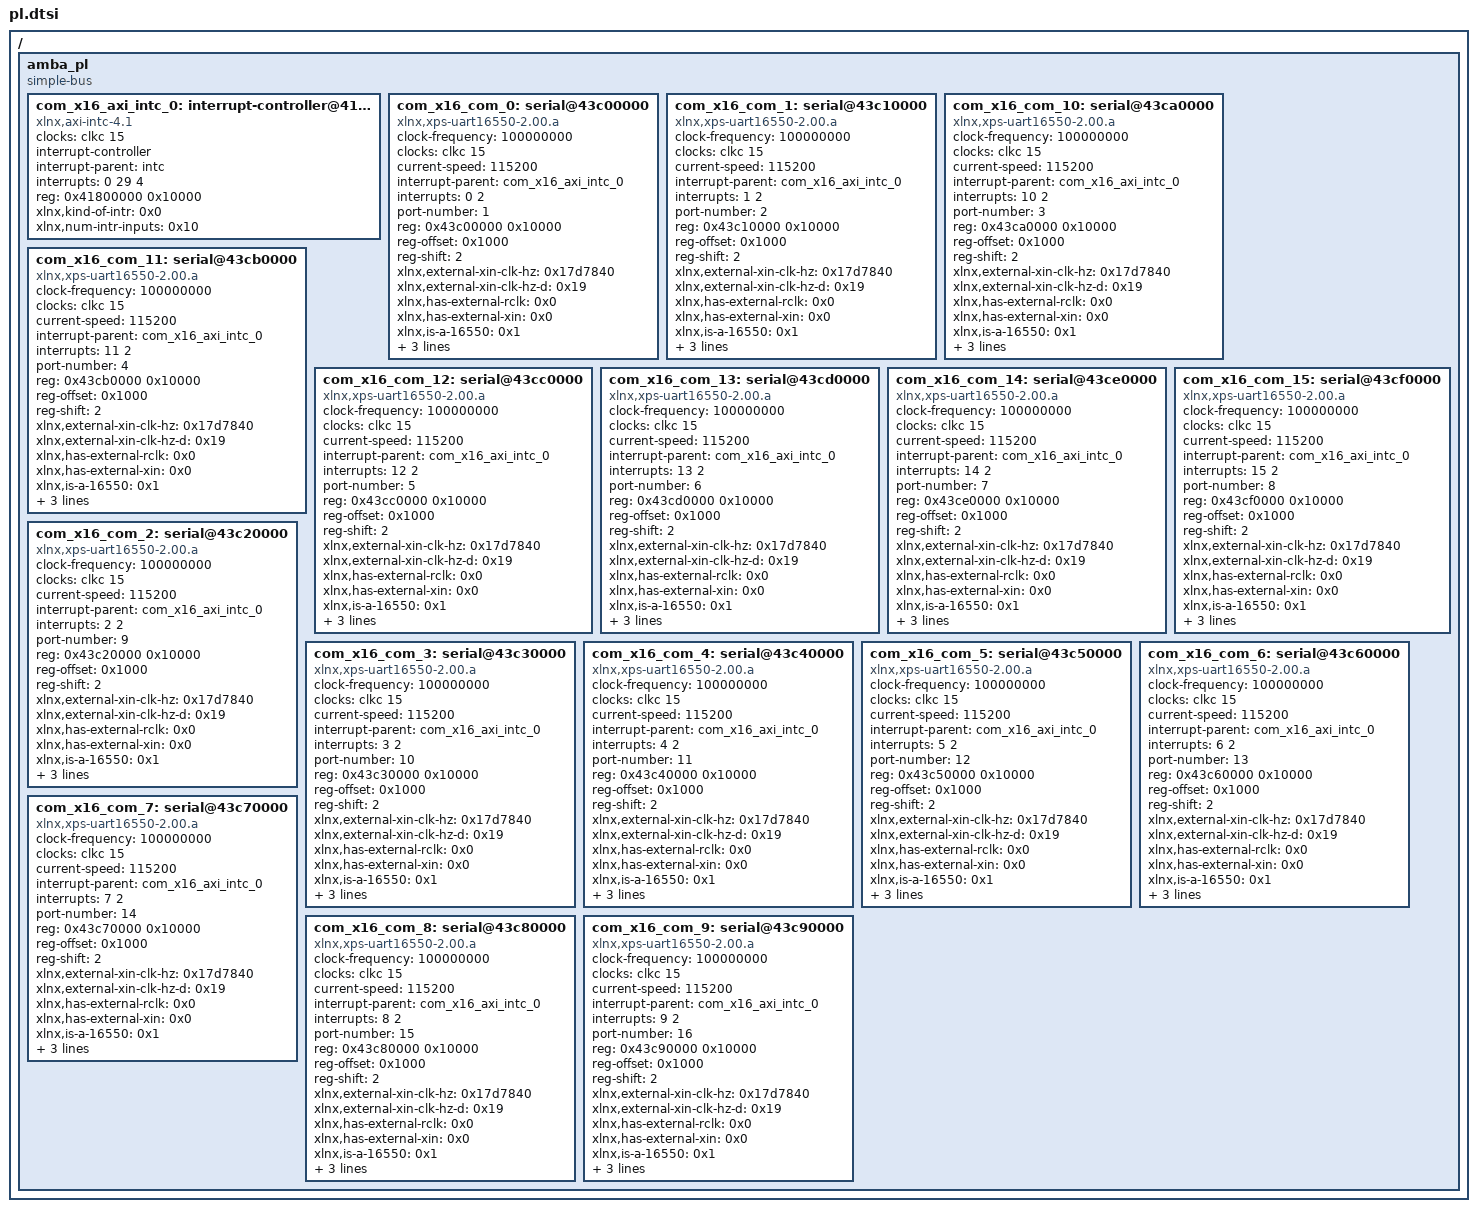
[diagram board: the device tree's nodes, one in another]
/*
 * CAUTION: This file is automatically generated by Xilinx.
 * Version: XSCT 2018.3.1
 * Today is: Tue Mar 17 23:05:40 2020
 */


/ {
	amba_pl: amba_pl {
		#address-cells = <1>;
		#size-cells = <1>;
		compatible = "simple-bus";
		ranges ;
		com_x16_axi_intc_0: interrupt-controller@41800000 {
			#interrupt-cells = <2>;
			clock-names = "s_axi_aclk";
			clocks = <&clkc 15>;
			compatible = "xlnx,axi-intc-4.1", "xlnx,xps-intc-1.00.a";
			interrupt-controller ;
			interrupt-names = "irq";
			interrupt-parent = <&intc>;
			interrupts = <0 29 4>;
			reg = <0x41800000 0x10000>;
			xlnx,kind-of-intr = <0x0>;
			xlnx,num-intr-inputs = <0x10>;
		};
		com_x16_com_0: serial@43c00000 {
			clock-frequency = <100000000>;
			clock-names = "s_axi_aclk";
			clocks = <&clkc 15>;
			compatible = "xlnx,xps-uart16550-2.00.a", "ns16550a";
			current-speed = <115200>;
			device_type = "serial";
			interrupt-names = "ip2intc_irpt";
			interrupt-parent = <&com_x16_axi_intc_0>;
			interrupts = <0 2>;
			port-number = <1>;
			reg = <0x43c00000 0x10000>;
			reg-offset = <0x1000>;
			reg-shift = <2>;
			xlnx,external-xin-clk-hz = <0x17d7840>;
			xlnx,external-xin-clk-hz-d = <0x19>;
			xlnx,has-external-rclk = <0x0>;
			xlnx,has-external-xin = <0x0>;
			xlnx,is-a-16550 = <0x1>;
			xlnx,s-axi-aclk-freq-hz-d = "100.0";
			xlnx,use-modem-ports = <0x1>;
			xlnx,use-user-ports = <0x1>;
		};
		com_x16_com_1: serial@43c10000 {
			clock-frequency = <100000000>;
			clock-names = "s_axi_aclk";
			clocks = <&clkc 15>;
			compatible = "xlnx,xps-uart16550-2.00.a", "ns16550a";
			current-speed = <115200>;
			device_type = "serial";
			interrupt-names = "ip2intc_irpt";
			interrupt-parent = <&com_x16_axi_intc_0>;
			interrupts = <1 2>;
			port-number = <2>;
			reg = <0x43c10000 0x10000>;
			reg-offset = <0x1000>;
			reg-shift = <2>;
			xlnx,external-xin-clk-hz = <0x17d7840>;
			xlnx,external-xin-clk-hz-d = <0x19>;
			xlnx,has-external-rclk = <0x0>;
			xlnx,has-external-xin = <0x0>;
			xlnx,is-a-16550 = <0x1>;
			xlnx,s-axi-aclk-freq-hz-d = "100.0";
			xlnx,use-modem-ports = <0x1>;
			xlnx,use-user-ports = <0x1>;
		};
		com_x16_com_10: serial@43ca0000 {
			clock-frequency = <100000000>;
			clock-names = "s_axi_aclk";
			clocks = <&clkc 15>;
			compatible = "xlnx,xps-uart16550-2.00.a", "ns16550a";
			current-speed = <115200>;
			device_type = "serial";
			interrupt-names = "ip2intc_irpt";
			interrupt-parent = <&com_x16_axi_intc_0>;
			interrupts = <10 2>;
			port-number = <3>;
			reg = <0x43ca0000 0x10000>;
			reg-offset = <0x1000>;
			reg-shift = <2>;
			xlnx,external-xin-clk-hz = <0x17d7840>;
			xlnx,external-xin-clk-hz-d = <0x19>;
			xlnx,has-external-rclk = <0x0>;
			xlnx,has-external-xin = <0x0>;
			xlnx,is-a-16550 = <0x1>;
			xlnx,s-axi-aclk-freq-hz-d = "100.0";
			xlnx,use-modem-ports = <0x1>;
			xlnx,use-user-ports = <0x1>;
		};
		com_x16_com_11: serial@43cb0000 {
			clock-frequency = <100000000>;
			clock-names = "s_axi_aclk";
			clocks = <&clkc 15>;
			compatible = "xlnx,xps-uart16550-2.00.a", "ns16550a";
			current-speed = <115200>;
			device_type = "serial";
			interrupt-names = "ip2intc_irpt";
			interrupt-parent = <&com_x16_axi_intc_0>;
			interrupts = <11 2>;
			port-number = <4>;
			reg = <0x43cb0000 0x10000>;
			reg-offset = <0x1000>;
			reg-shift = <2>;
			xlnx,external-xin-clk-hz = <0x17d7840>;
			xlnx,external-xin-clk-hz-d = <0x19>;
			xlnx,has-external-rclk = <0x0>;
			xlnx,has-external-xin = <0x0>;
			xlnx,is-a-16550 = <0x1>;
			xlnx,s-axi-aclk-freq-hz-d = "100.0";
			xlnx,use-modem-ports = <0x1>;
			xlnx,use-user-ports = <0x1>;
		};
		com_x16_com_12: serial@43cc0000 {
			clock-frequency = <100000000>;
			clock-names = "s_axi_aclk";
			clocks = <&clkc 15>;
			compatible = "xlnx,xps-uart16550-2.00.a", "ns16550a";
			current-speed = <115200>;
			device_type = "serial";
			interrupt-names = "ip2intc_irpt";
			interrupt-parent = <&com_x16_axi_intc_0>;
			interrupts = <12 2>;
			port-number = <5>;
			reg = <0x43cc0000 0x10000>;
			reg-offset = <0x1000>;
			reg-shift = <2>;
			xlnx,external-xin-clk-hz = <0x17d7840>;
			xlnx,external-xin-clk-hz-d = <0x19>;
			xlnx,has-external-rclk = <0x0>;
			xlnx,has-external-xin = <0x0>;
			xlnx,is-a-16550 = <0x1>;
			xlnx,s-axi-aclk-freq-hz-d = "100.0";
			xlnx,use-modem-ports = <0x1>;
			xlnx,use-user-ports = <0x1>;
		};
		com_x16_com_13: serial@43cd0000 {
			clock-frequency = <100000000>;
			clock-names = "s_axi_aclk";
			clocks = <&clkc 15>;
			compatible = "xlnx,xps-uart16550-2.00.a", "ns16550a";
			current-speed = <115200>;
			device_type = "serial";
			interrupt-names = "ip2intc_irpt";
			interrupt-parent = <&com_x16_axi_intc_0>;
			interrupts = <13 2>;
			port-number = <6>;
			reg = <0x43cd0000 0x10000>;
			reg-offset = <0x1000>;
			reg-shift = <2>;
			xlnx,external-xin-clk-hz = <0x17d7840>;
			xlnx,external-xin-clk-hz-d = <0x19>;
			xlnx,has-external-rclk = <0x0>;
			xlnx,has-external-xin = <0x0>;
			xlnx,is-a-16550 = <0x1>;
			xlnx,s-axi-aclk-freq-hz-d = "100.0";
			xlnx,use-modem-ports = <0x1>;
			xlnx,use-user-ports = <0x1>;
		};
		com_x16_com_14: serial@43ce0000 {
			clock-frequency = <100000000>;
			clock-names = "s_axi_aclk";
			clocks = <&clkc 15>;
			compatible = "xlnx,xps-uart16550-2.00.a", "ns16550a";
			current-speed = <115200>;
			device_type = "serial";
			interrupt-names = "ip2intc_irpt";
			interrupt-parent = <&com_x16_axi_intc_0>;
			interrupts = <14 2>;
			port-number = <7>;
			reg = <0x43ce0000 0x10000>;
			reg-offset = <0x1000>;
			reg-shift = <2>;
			xlnx,external-xin-clk-hz = <0x17d7840>;
			xlnx,external-xin-clk-hz-d = <0x19>;
			xlnx,has-external-rclk = <0x0>;
			xlnx,has-external-xin = <0x0>;
			xlnx,is-a-16550 = <0x1>;
			xlnx,s-axi-aclk-freq-hz-d = "100.0";
			xlnx,use-modem-ports = <0x1>;
			xlnx,use-user-ports = <0x1>;
		};
		com_x16_com_15: serial@43cf0000 {
			clock-frequency = <100000000>;
			clock-names = "s_axi_aclk";
			clocks = <&clkc 15>;
			compatible = "xlnx,xps-uart16550-2.00.a", "ns16550a";
			current-speed = <115200>;
			device_type = "serial";
			interrupt-names = "ip2intc_irpt";
			interrupt-parent = <&com_x16_axi_intc_0>;
			interrupts = <15 2>;
			port-number = <8>;
			reg = <0x43cf0000 0x10000>;
			reg-offset = <0x1000>;
			reg-shift = <2>;
			xlnx,external-xin-clk-hz = <0x17d7840>;
			xlnx,external-xin-clk-hz-d = <0x19>;
			xlnx,has-external-rclk = <0x0>;
			xlnx,has-external-xin = <0x0>;
			xlnx,is-a-16550 = <0x1>;
			xlnx,s-axi-aclk-freq-hz-d = "100.0";
			xlnx,use-modem-ports = <0x1>;
			xlnx,use-user-ports = <0x1>;
		};
		com_x16_com_2: serial@43c20000 {
			clock-frequency = <100000000>;
			clock-names = "s_axi_aclk";
			clocks = <&clkc 15>;
			compatible = "xlnx,xps-uart16550-2.00.a", "ns16550a";
			current-speed = <115200>;
			device_type = "serial";
			interrupt-names = "ip2intc_irpt";
			interrupt-parent = <&com_x16_axi_intc_0>;
			interrupts = <2 2>;
			port-number = <9>;
			reg = <0x43c20000 0x10000>;
			reg-offset = <0x1000>;
			reg-shift = <2>;
			xlnx,external-xin-clk-hz = <0x17d7840>;
			xlnx,external-xin-clk-hz-d = <0x19>;
			xlnx,has-external-rclk = <0x0>;
			xlnx,has-external-xin = <0x0>;
			xlnx,is-a-16550 = <0x1>;
			xlnx,s-axi-aclk-freq-hz-d = "100.0";
			xlnx,use-modem-ports = <0x1>;
			xlnx,use-user-ports = <0x1>;
		};
		com_x16_com_3: serial@43c30000 {
			clock-frequency = <100000000>;
			clock-names = "s_axi_aclk";
			clocks = <&clkc 15>;
			compatible = "xlnx,xps-uart16550-2.00.a", "ns16550a";
			current-speed = <115200>;
			device_type = "serial";
			interrupt-names = "ip2intc_irpt";
			interrupt-parent = <&com_x16_axi_intc_0>;
			interrupts = <3 2>;
			port-number = <10>;
			reg = <0x43c30000 0x10000>;
			reg-offset = <0x1000>;
			reg-shift = <2>;
			xlnx,external-xin-clk-hz = <0x17d7840>;
			xlnx,external-xin-clk-hz-d = <0x19>;
			xlnx,has-external-rclk = <0x0>;
			xlnx,has-external-xin = <0x0>;
			xlnx,is-a-16550 = <0x1>;
			xlnx,s-axi-aclk-freq-hz-d = "100.0";
			xlnx,use-modem-ports = <0x1>;
			xlnx,use-user-ports = <0x1>;
		};
		com_x16_com_4: serial@43c40000 {
			clock-frequency = <100000000>;
			clock-names = "s_axi_aclk";
			clocks = <&clkc 15>;
			compatible = "xlnx,xps-uart16550-2.00.a", "ns16550a";
			current-speed = <115200>;
			device_type = "serial";
			interrupt-names = "ip2intc_irpt";
			interrupt-parent = <&com_x16_axi_intc_0>;
			interrupts = <4 2>;
			port-number = <11>;
			reg = <0x43c40000 0x10000>;
			reg-offset = <0x1000>;
			reg-shift = <2>;
			xlnx,external-xin-clk-hz = <0x17d7840>;
			xlnx,external-xin-clk-hz-d = <0x19>;
			xlnx,has-external-rclk = <0x0>;
			xlnx,has-external-xin = <0x0>;
			xlnx,is-a-16550 = <0x1>;
			xlnx,s-axi-aclk-freq-hz-d = "100.0";
			xlnx,use-modem-ports = <0x1>;
			xlnx,use-user-ports = <0x1>;
		};
		com_x16_com_5: serial@43c50000 {
			clock-frequency = <100000000>;
			clock-names = "s_axi_aclk";
			clocks = <&clkc 15>;
			compatible = "xlnx,xps-uart16550-2.00.a", "ns16550a";
			current-speed = <115200>;
			device_type = "serial";
			interrupt-names = "ip2intc_irpt";
			interrupt-parent = <&com_x16_axi_intc_0>;
			interrupts = <5 2>;
			port-number = <12>;
			reg = <0x43c50000 0x10000>;
			reg-offset = <0x1000>;
			reg-shift = <2>;
			xlnx,external-xin-clk-hz = <0x17d7840>;
			xlnx,external-xin-clk-hz-d = <0x19>;
			xlnx,has-external-rclk = <0x0>;
			xlnx,has-external-xin = <0x0>;
			xlnx,is-a-16550 = <0x1>;
			xlnx,s-axi-aclk-freq-hz-d = "100.0";
			xlnx,use-modem-ports = <0x1>;
			xlnx,use-user-ports = <0x1>;
		};
		com_x16_com_6: serial@43c60000 {
			clock-frequency = <100000000>;
			clock-names = "s_axi_aclk";
			clocks = <&clkc 15>;
			compatible = "xlnx,xps-uart16550-2.00.a", "ns16550a";
			current-speed = <115200>;
			device_type = "serial";
			interrupt-names = "ip2intc_irpt";
			interrupt-parent = <&com_x16_axi_intc_0>;
			interrupts = <6 2>;
			port-number = <13>;
			reg = <0x43c60000 0x10000>;
			reg-offset = <0x1000>;
			reg-shift = <2>;
			xlnx,external-xin-clk-hz = <0x17d7840>;
			xlnx,external-xin-clk-hz-d = <0x19>;
			xlnx,has-external-rclk = <0x0>;
			xlnx,has-external-xin = <0x0>;
			xlnx,is-a-16550 = <0x1>;
			xlnx,s-axi-aclk-freq-hz-d = "100.0";
			xlnx,use-modem-ports = <0x1>;
			xlnx,use-user-ports = <0x1>;
		};
		com_x16_com_7: serial@43c70000 {
			clock-frequency = <100000000>;
			clock-names = "s_axi_aclk";
			clocks = <&clkc 15>;
			compatible = "xlnx,xps-uart16550-2.00.a", "ns16550a";
			current-speed = <115200>;
			device_type = "serial";
			interrupt-names = "ip2intc_irpt";
			interrupt-parent = <&com_x16_axi_intc_0>;
			interrupts = <7 2>;
			port-number = <14>;
			reg = <0x43c70000 0x10000>;
			reg-offset = <0x1000>;
			reg-shift = <2>;
			xlnx,external-xin-clk-hz = <0x17d7840>;
			xlnx,external-xin-clk-hz-d = <0x19>;
			xlnx,has-external-rclk = <0x0>;
			xlnx,has-external-xin = <0x0>;
			xlnx,is-a-16550 = <0x1>;
			xlnx,s-axi-aclk-freq-hz-d = "100.0";
			xlnx,use-modem-ports = <0x1>;
			xlnx,use-user-ports = <0x1>;
		};
		com_x16_com_8: serial@43c80000 {
			clock-frequency = <100000000>;
			clock-names = "s_axi_aclk";
			clocks = <&clkc 15>;
			compatible = "xlnx,xps-uart16550-2.00.a", "ns16550a";
			current-speed = <115200>;
			device_type = "serial";
			interrupt-names = "ip2intc_irpt";
			interrupt-parent = <&com_x16_axi_intc_0>;
			interrupts = <8 2>;
			port-number = <15>;
			reg = <0x43c80000 0x10000>;
			reg-offset = <0x1000>;
			reg-shift = <2>;
			xlnx,external-xin-clk-hz = <0x17d7840>;
			xlnx,external-xin-clk-hz-d = <0x19>;
			xlnx,has-external-rclk = <0x0>;
			xlnx,has-external-xin = <0x0>;
			xlnx,is-a-16550 = <0x1>;
			xlnx,s-axi-aclk-freq-hz-d = "100.0";
			xlnx,use-modem-ports = <0x1>;
			xlnx,use-user-ports = <0x1>;
		};
		com_x16_com_9: serial@43c90000 {
			clock-frequency = <100000000>;
			clock-names = "s_axi_aclk";
			clocks = <&clkc 15>;
			compatible = "xlnx,xps-uart16550-2.00.a", "ns16550a";
			current-speed = <115200>;
			device_type = "serial";
			interrupt-names = "ip2intc_irpt";
			interrupt-parent = <&com_x16_axi_intc_0>;
			interrupts = <9 2>;
			port-number = <16>;
			reg = <0x43c90000 0x10000>;
			reg-offset = <0x1000>;
			reg-shift = <2>;
			xlnx,external-xin-clk-hz = <0x17d7840>;
			xlnx,external-xin-clk-hz-d = <0x19>;
			xlnx,has-external-rclk = <0x0>;
			xlnx,has-external-xin = <0x0>;
			xlnx,is-a-16550 = <0x1>;
			xlnx,s-axi-aclk-freq-hz-d = "100.0";
			xlnx,use-modem-ports = <0x1>;
			xlnx,use-user-ports = <0x1>;
		};
	};
};
